# i2c_reva_me11 register map
Registers are 32-bit, access not given, no defined reset value unless marked. A register's access mark holds for its fields unless they carry their own. Offsets are from the block's base; lines under a group give offsets from that group; [hi:lo] are bit positions; {n}, {i} and the like mark numbered series; 'fields as' and 'values as' point back to an identical list; <NAME> marks a mode.

## Memory map
0x4001D000 I2C0 size 0x1000 — Inter-Integrated Circuit.

## Interrupts
13 I2C0 — I2C0 IRQ

## I2C0 — Inter-Integrated Circuit.
Base 0x4001D000
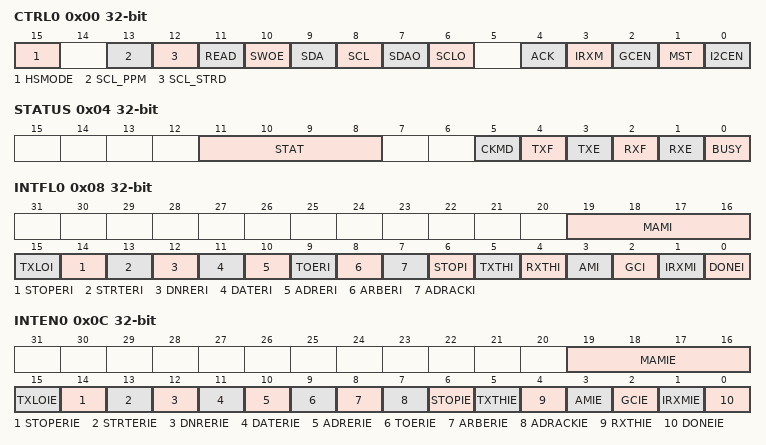
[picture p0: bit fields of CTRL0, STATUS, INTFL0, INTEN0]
0x00 CTRL0 — Control Register0.
  [15] HSMODE — Hs-mode Enable.
    0=dis (Hs-mode disabled.); 1=en (Hs-mode enabled.)
  [13] SCL_PPM rw — SCL Push-Pull Mode. This bit controls whether SCL is operated in a the I2C standard open-drain mode, or in a non-standard push-pull mode where the Hi-Z output isreplaced with Drive-1. The non-standard mode should only be used when operating as a master and communicating with slaves that are guaranteed to never drive SCL low.
    0=dis (Standard open-drain operation: drive low for 0, Hi-Z for 1); 1=en (Non-standard push-pull operation: drive low for 0, drive high for 1)
  [12] SCL_STRD rw — This bit will disable slave clock stretching when set.
    0=en (Slave clock stretching enabled.); 1=dis (Slave clock stretching disabled.)
  [11] READ ro — Read. This bit reflects the R/W bit of an address match (AMI = 1) or general call match(GCI = 1). This bit is valid 3 cycles after the relevant interrupt bit is set.
    0=write; 1=read
  [10] SWOE rw — Software Output Enable.
    0=outputs_disable (I2C Outputs SCLO and SDAO disabled.); 1=outputs_enable (I2C Outputs SCLO and SDAO enabled.)
  [9] SDA ro — SDA status. This bit reflects the logic gate of SDA signal.
  [8] SCL ro — SCL status. This bit reflects the logic gate of SCL signal.
  [7] SDAO rw — SDA Output. This bits control SDA output when SWOE = 1.
    0=drive_sda_low; 1=release_sda
  [6] SCLO rw — SCL Output. This bits control SCL output when SWOE =1.
    0=drive_scl_low; 1=release_scl
  [4] ACK rw — Data Acknowledge. This bit defines the acknowledge bit returned by the I2C receiver while IRXM = 1 HW forces ACK to 0 when IRXM = 0.
    0=ack (return ACK (pulling SDA LOW).); 1=nack (return NACK (leaving SDA HIGH).)
  [3] IRXM rw — Interactive Receive Mode.
    0=dis (Disable Interactive Receive Mode.); 1=en (Enable Interactive Receive Mode.)
  [2] GCEN rw — General Call Address Enable.
    0=dis (Ignore Gneral Call Address.); 1=en (Acknowledge general call address.)
  [1] MST rw — Master Mode Enable.
    0=slave_mode; 1=master_mode
  [0] I2CEN rw — I2C Enable.
    0=dis (Disable I2C.); 1=en (enable I2C.)
0x04 STATUS
  [11:8] STAT — Controller Status.
    0=idle (Controller Idle.); 1=mtx_addr (master Transmit address.); 2=mrx_addr_ack (Master Receive address ACK.); 3=mtx_ex_addr (Master Transmit extended address.); 4=mrx_ex_addr (Master Receive extended address ACK.); 5=srx_addr (Slave Receive address.); 6=stx_addr_ack (Slave Transmit address ACK.); 7=srx_ex_addr (Slave Receive extended address.); 8=stx_ex_addr_ack (Slave Transmit extended address ACK.); 9=tx (Transmit data (master or slave).); 10=rx_ack (Receive data ACK (master or slave).); 11=rx (Receive data (master or slave).); 12=tx_ack (Transmit data ACK (master or slave).); 13=NACK stage (master or slave); 15=Bystander state (ongoing transaction but not participant- another master addressing another slave)
  [5] CKMD ro — Clock Mode.
    0=not_actively_driving_scl_clock (Device not actively driving SCL clock cycles.); 1=actively_driving_scl_clock (Device operating as master and actively driving SCL clock cycles.)
  [4] TXF — TX Full.
    0=not_empty; 1=empty
  [3] TXE — TX Empty.
    0=not_empty; 1=empty
  [2] RXF ro — RX Full.
    0=not_full; 1=full
  [1] RXE ro — RX empty.
    0=not_empty; 1=empty
  [0] BUSY ro — Bus Status.
    0=idle (I2C Bus Idle.); 1=busy (I2C Bus Busy.)
0x08 INTFL0 — Interrupt Status Register.
  [19:16] MAMI — Multiple Slave Address Match Interrupt.
  [15] TXLOI — Transmit Lock Out Interrupt.
  [14] STOPERI — Stop Error Interrupt.
    0=inactive (No Interrupt is Pending.); 1=pending (An interrupt is pending.)
  [13] STRTERI — Start Error Interrupt.
    values as STOPERI
  [12] DNRERI — Do Not Respond Error Interrupt.
    values as STOPERI
  [11] DATERI — Data NACK Error Interrupt.
    values as STOPERI
  [10] ADRERI — Address NACK Error Interrupt.
    values as STOPERI
  [9] TOERI — timeout Error Interrupt.
    values as STOPERI
  [8] ARBERI — Arbritation error Interrupt.
    values as STOPERI
  [7] ADRACKI — Address Acknowledge Interrupt.
    values as STOPERI
  [6] STOPI — STOP Interrupt.
    0=inactive (No interrupt is pending.); 1=pending (An interrupt is pending. TX_FIFO has equal or less bytes than the threshold.)
  [5] TXTHI — Transmit Threshold Interrupt. This bit is automaticcaly cleared when TX_FIFO is above the threshold level.
    values as STOPI
  [4] RXTHI — Receive Threshold Interrupt. This bit is automaticcaly cleared when RX_FIFO is below the threshold level.
    0=inactive (No interrupt is pending.); 1=pending (An interrupt is pending. RX_FIFO equal or more bytes than the threshold.)
  [3] AMI — Slave Address Match Interrupt.
    values as STOPERI
  [2] GCI — Slave General Call Address Match Interrupt.
    values as STOPERI
  [1] IRXMI — Interactive Receive Interrupt.
    values as STOPERI
  [0] DONEI — Transfer Done Interrupt.
    values as STOPERI
0x0C INTEN0 rw — Interrupt Enable Register.
  [19:16] MAMIE — Multiple Slave Address Match Interrupt Enable.
  [15] TXLOIE — TX FIFO Locked Out Interrupt.
    0=dis (Interrupt disabled.); 1=en (Interrupt enabled when TXLOIE = 1.)
  [14] STOPERIE — Out of Sequence STOP condition detected interrupt.
    0=dis (Interrupt disabled.); 1=en (Interrupt enabled.)
  [13] STRTERIE — Out of Sequence START condition detected interrupt.
    0=dis (Interrupt disabled.); 1=en (Interrupt enabled.)
  [12] DNRERIE — Slave Mode Do Not Respond Interrupt.
    0=dis (Interrupt disabled.); 1=en (Interrupt enabled.)
  [11] DATERIE — Master Mode Data NACK Received Interrupt.
    0=dis (Interrupt disabled.); 1=en (Interrupt enabled.)
  [10] ADRERIE — Master Mode Address NACK Received Interrupt.
    0=dis (Interrupt disabled.); 1=en (Interrupt enabled.)
  [9] TOERIE — Timeout Error Interrupt Enable.
    0=dis (Interrupt disabled.); 1=en (Interrupt enabled.)
  [8] ARBERIE — Master Mode Arbitration Lost Interrupt.
    0=dis (Interrupt disabled.); 1=en (Interrupt enabled.)
  [7] ADRACKIE — Received Address ACK from Slave Interrupt.
    0=dis (Interrupt disabled.); 1=en (Interrupt enabled.)
  [6] STOPIE — Stop Interrupt Enable
    0=dis (Interrupt disabled.); 1=en (Interrupt enabled when STOP = 1.)
  [5] TXTHIE — TX FIFO Below Treshold Level Interrupt Enable.
    0=dis (Interrupt disabled.); 1=en (Interrupt enabled.)
  [4] RXTHIE — RX FIFO Above Treshold Level Interrupt Enable.
    0=dis (Interrupt disabled.); 1=en (Interrupt enabled.)
  [3] AMIE — Slave mode incoming address match interrupt.
    0=dis (Interrupt disabled.); 1=en (Interrupt enabled when ADDR_MATCH = 1.)
  [2] GCIE — Slave mode general call address match received input enable.
    0=dis (Interrupt disabled.); 1=en (Interrupt enabled when GEN_CTRL_ADDR = 1.)
  [1] IRXMIE
    0=dis (Interrupt disabled.); 1=en (Interrupt enabled when RX_MODE = 1.)
  [0] DONEIE — Transfer Done Interrupt Enable.
    0=dis (Interrupt disabled.); 1=en (Interrupt enabled when DONE = 1.)
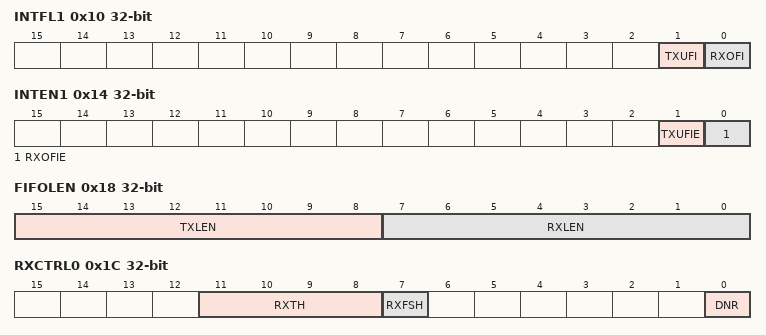
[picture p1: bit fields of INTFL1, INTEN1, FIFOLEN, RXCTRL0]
0x10 INTFL1 — Interrupt Status Register 1.
  [1] TXUFI — Transmit Underflow Interrupt. When operating as a slave transmitter, this bit is set when you reach the first data bit and the TX FIFO is empty and the master is still asking for more data (i.e the master hasn't sent a NACK yet).
    values as INTFL0.STOPERI
  [0] RXOFI — Receiver Overflow Interrupt. When operating as a slave receiver, this bit is set when you reach the first data bit and the RX FIFO and shift register are both full.
    values as INTFL0.STOPERI
0x14 INTEN1 rw — Interrupt Staus Register 1.
  [1] TXUFIE — Transmit Underflow Interrupt Enable.
    0=dis (No Interrupt is Pending.); 1=en (An interrupt is pending.)
  [0] RXOFIE — Receiver Overflow Interrupt Enable.
    values as TXUFIE
0x18 FIFOLEN ro — FIFO Configuration Register.
  [15:8] TXLEN — Transmit FIFO Length.
  [7:0] RXLEN — Receive FIFO Length.
0x1C RXCTRL0 — Receive Control Register 0.
  [11:8] RXTH — Receive FIFO Threshold. These bits define the RX_FIFO interrupt threshold.
  [7] RXFSH — Receive FIFO Flush. This bit is automatically cleared to 0 after the operation. Setting this bit to 1 will affect RX_FIFO status.
    0=not_flushed (FIFO not flushed.); 1=Flush RX_FIFO
  [0] DNR — Do Not Respond.
    0=respond (Always respond to address match.); 1=not_respond_rx_fifo_empty (Do not respond to address match when RX_FIFO is not empty.)
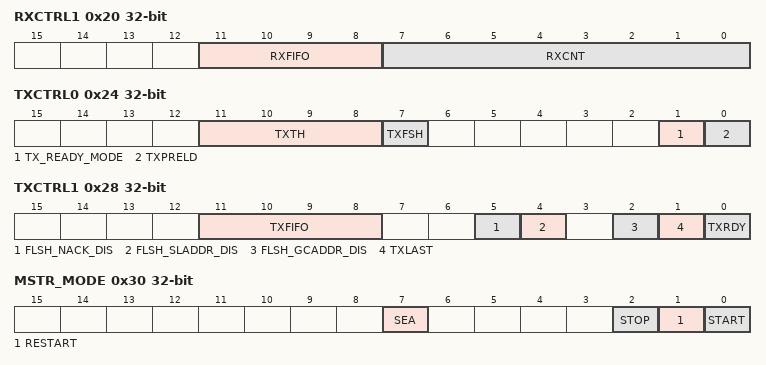
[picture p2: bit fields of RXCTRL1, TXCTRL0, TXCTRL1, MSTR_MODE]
0x20 RXCTRL1 — Receive Control Register 1.
  [11:8] RXFIFO ro — Receive FIFO Count. These bits reflect the number of byte in the RX_FIFO. These bits are flushed when I2CEN = 0.
  [7:0] RXCNT — Receive Count Bits. These bits define the number of bytes to be received in a transaction, except for the case RXCNT = 0. RXCNT = 0 means 256 bytes to be received in a transaction.
0x24 TXCTRL0 — Transmit Control Register 0.
  [11:8] TXTH — Transmit FIFO Threshold. These bits define the TX_FIFO interrupt threshold.
  [7] TXFSH — Transmit FIFO Flush. This bit is automatically cleared to 0 after the operation.
    0=not_flushed (FIFO not flushed.); 1=Flush TX_FIFO
  [1] TX_READY_MODE — Transmit FIFO Ready Manual Mode.
    0=en (HW control of I2CTXRDY enabled.); 1=dis (HW control of I2CTXRDY disabled.)
  [0] TXPRELD — Transmit FIFO Preaload Mode. Setting this bit will allow for high speed application to preload the transmit FIFO prior to Slave Address Match.
0x28 TXCTRL1 — Transmit Control Register 1.
  [11:8] TXFIFO ro — Transmit FIFO Count. These bits reflect the number of bytes in the TX_FIFO.
  [5] FLSH_NACK_DIS — TX FIFO Auto Flush Disable for NACK. Setting this field to 1 disables the TX FIFO Automatic Flush when a NACK is received at the end of a slave transaction.
    0=autoflush_en (The TX FIFO is automatically flushed if a NACK is received at the end of a slave transaction.); 1=autoflush_dis (The TX FIFO is not flushed when a NACK is received at the end of a slave transaction.)
  [4] FLSH_SLADDR_DIS — TX FIFO Auto Flush Disable for Slave Address Match. Setting this field to 1 disables the TX FIFO Automatic Flush when a Slave Address Match occurs.
    0=autoflush_en (The TX FIFO is automatically flushed on a Slave Address Match.); 1=autoflush_dis (The TX FIFO is not flushed on a Slave Address Match.)
  [2] FLSH_GCADDR_DIS — TX FIFO Auto Flush Disable on General Call Address Match.Setting this field to 1 disables the TX FIFO Automatic Flush when a General Call Address Match occurs.
    0=autoflush_en (The TX FIFO is automatically flushed on a General Call Address Match.); 1=autoflush_dis (The TX FIFO is not flushed on a General Call Address Match.)
  [1] TXLAST — Transmit Last. This bit is used in slave mod only. Do not use when preloading (cleared by hardware).
    0=Hold SCL low on TX_FIFO empty; 1=End transaction on TX_FIFO empty
  [0] TXRDY — Transmit FIFO Preload Ready.
0x2C FIFO — Data Register.
  [7:0] DATA — Data is read from or written to this location. Transmit and receive FIFO are separate but both are addressed at this location.
0x30 MSTR_MODE — Master Control Register.
  [7] SEA — Slave Extend Address Select.
    0=7_bits_address (7-bit address.); 1=10_bits_address (10-bit address.)
  [2] STOP — Setting this bit to 1 will generate a STOP condition.
  [1] RESTART — Setting this bit to 1 will generate a repeated START.
  [0] START — Setting this bit to 1 will start a master transfer.
0x34 CLKLO — Clock Low Register.
  [8:0] SCL_LO — Clock low. In master mode, these bits define the SCL low period. In slave mode, these bits define the time SCL will be held low after data is outputted.
0x38 CLKHI — Clock high Register.
  [8:0] SCL_HI — Clock High. In master mode, these bits define the SCL high period.
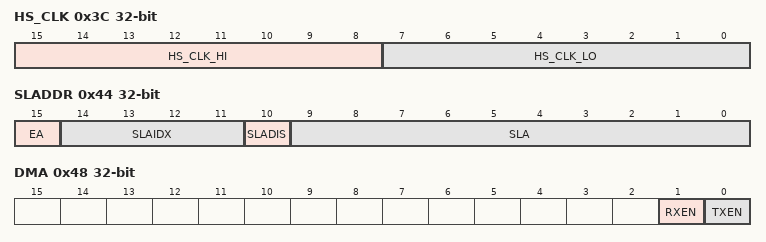
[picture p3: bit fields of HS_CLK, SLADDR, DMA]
0x3C HS_CLK — HS-Mode Clock Control Register
  [15:8] HS_CLK_HI — Slave Address.
  [7:0] HS_CLK_LO — Slave Address.
0x40 TIMEOUT
  [15:0] TO — Timeout
0x44 SLADDR — Slave Address Register.
  [15] EA — Extended Address Select.
    values as MSTR_MODE.SEA
  [14:11] SLAIDX — Slave Address Index.
  [10] SLADIS — Slave Address Disable.
  [9:0] SLA — Slave Address.
0x48 DMA
  [1] RXEN — RX channel enable.
    0=dis (Disable.); 1=en (Enable.)
  [0] TXEN — TX channel enable.
    0=dis (Disable.); 1=en (Enable.)
